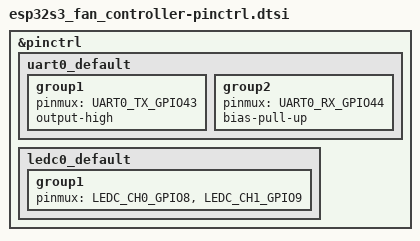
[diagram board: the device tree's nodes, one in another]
/*
 * Copyright (c) 2024 Espressif Systems (Shanghai) Co., Ltd.
 *
 * SPDX-License-Identifier: Apache-2.0
 */

#include <zephyr/dt-bindings/pinctrl/esp-pinctrl-common.h>
#include <zephyr/dt-bindings/pinctrl/esp32s3-pinctrl.h>
#include <zephyr/dt-bindings/pinctrl/esp32s3-gpio-sigmap.h>

&pinctrl {
	uart0_default: uart0_default {
		group1 {
			pinmux = <UART0_TX_GPIO43>;
			output-high;
		};

		group2 {
			pinmux = <UART0_RX_GPIO44>;
			bias-pull-up;
		};
	};

	ledc0_default: ledc0_default {
		group1 {
			pinmux = <LEDC_CH0_GPIO8>,
				 <LEDC_CH1_GPIO9>;
		};
	};
};
